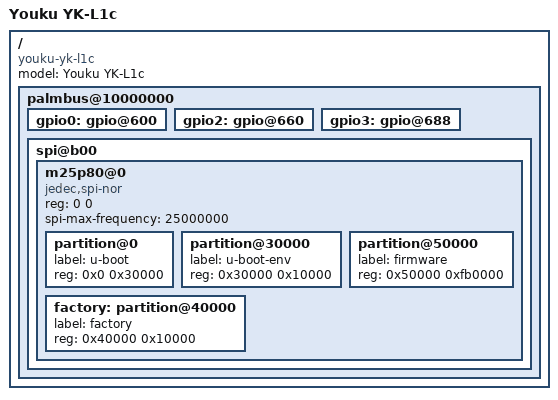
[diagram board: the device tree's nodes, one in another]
/dts-v1/;

/include/ "YOUKU-YK-L1.dtsi"

/ {
	compatible = "youku-yk-l1c", "ralink,mt7620a-soc";
	model = "Youku YK-L1c";

	palmbus@10000000 {
		gpio0: gpio@600 {
			status = "okay";
		};

		gpio2: gpio@660 {
			status = "okay";
		};

		gpio3: gpio@688 {
			status = "okay";
		};

		spi@b00 {
			status = "okay";

			m25p80@0 {
				#address-cells = <1>;
				#size-cells = <1>;
				compatible = "jedec,spi-nor";
				reg = <0 0>;
				spi-max-frequency = <25000000>;

				partition@0 {
					label = "u-boot";
					reg = <0x0 0x30000>;
				};

				partition@30000 {
					label = "u-boot-env";
					reg = <0x30000 0x10000>;
				};

				factory: partition@40000 {
					label = "factory";
					reg = <0x40000 0x10000>;
				};

				partition@50000 {
					label = "firmware";
					reg = <0x50000 0xfb0000>;
				};
			};
		};
	};
};
